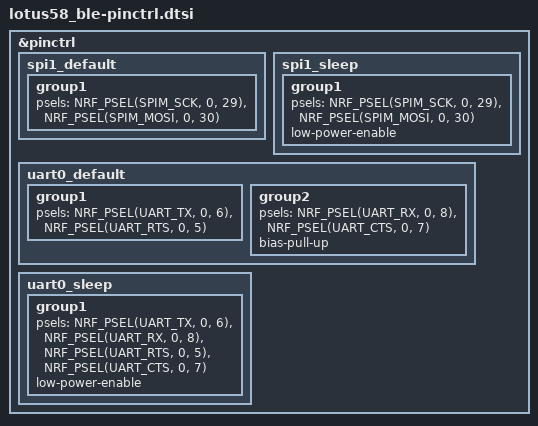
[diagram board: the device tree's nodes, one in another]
// SPDX-License-Identifier: MIT

&pinctrl {
  spi1_default: spi1_default {
    group1 {
      psels
        = <NRF_PSEL(SPIM_SCK, 0, 29)>
        , <NRF_PSEL(SPIM_MOSI, 0, 30)>
        ;
    };
  };

  spi1_sleep: spi1_sleep {
    group1 {
      psels
        = <NRF_PSEL(SPIM_SCK, 0, 29)>
        , <NRF_PSEL(SPIM_MOSI, 0, 30)>
        ;
      low-power-enable;
    };
  };

  uart0_default: uart0_default {
    group1 {
      psels = <NRF_PSEL(UART_TX, 0, 6)>, <NRF_PSEL(UART_RTS, 0, 5)>;
    };
    group2 {
      psels = <NRF_PSEL(UART_RX, 0, 8)>, <NRF_PSEL(UART_CTS, 0, 7)>;
      bias-pull-up;
    };
  };

  uart0_sleep: uart0_sleep {
    group1 {
      psels
        = <NRF_PSEL(UART_TX, 0, 6)>
        , <NRF_PSEL(UART_RX, 0, 8)>
        , <NRF_PSEL(UART_RTS, 0, 5)>
        , <NRF_PSEL(UART_CTS, 0, 7)>
        ;
      low-power-enable;
    };
  };
};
